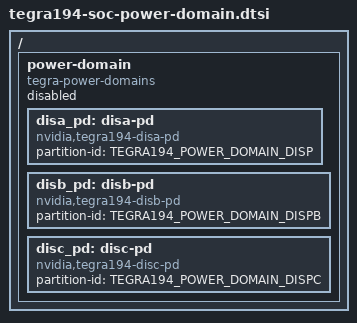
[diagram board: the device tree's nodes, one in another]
/ {
       power-domain {
               compatible = "tegra-power-domains";
               status = "disabled";

               disa_pd: disa-pd {
                       compatible = "nvidia,tegra194-disa-pd";
                       #power-domain-cells = <0>;
                       partition-id = <TEGRA194_POWER_DOMAIN_DISP>;
               };

               disb_pd: disb-pd {
                       compatible = "nvidia,tegra194-disb-pd";
                       #power-domain-cells = <0>;
                       partition-id = <TEGRA194_POWER_DOMAIN_DISPB>;
               };

               disc_pd: disc-pd {
                       compatible = "nvidia,tegra194-disc-pd";
                       #power-domain-cells = <0>;
                       partition-id = <TEGRA194_POWER_DOMAIN_DISPC>;
               };
       };
};
